# SPC1169 register map
File version: 2022071043481212
CPU: cm4 r1p0, little endian, no MPU, FPU, 4 interrupt priority bits
Registers are 32-bit, read-write, reset 0x0 unless marked. A register's access mark holds for its fields unless they carry their own. Offsets are from the block's base; [hi:lo] are bit positions; {n}, {i} and the like mark numbered series; 'fields as' and 'values as' point back to an identical list.

## SYSTEM
Base 0x40000000
0x00 CID0 ro — Chip ID Register 0
  [31:0] VAL — 32 LSBs of the 64-bit chip ID
0x04 CID1 ro — Chip ID Register 1
  [31:0] VAL — 32 MSBs of the 64-bit chip ID
0x08 UID0 ro — Unique ID Register 0
  [31:0] VAL — 32 LSBs of the 64-bit unique ID
0x0C UID1 ro — Unique ID Register 1
  [31:0] VAL — 32 MSBs of the 64-bit unique ID
0x10 RND0 ro — Random Number Register 0
  [31:0] VAL — 32 LSBs of the 64-bit random number
0x14 RND1 ro — Random Number Register 1
  [31:0] VAL — 32 MSBs of the 64-bit random number
0x18 REV0 ro reset 0x63681010 — Revision Information Register 0
  [31:0] VAL — 32 LSBs of the 64-bit revision number
0x1C REV1 ro reset 0x20200200 — Revision Information Register 1
  [31:0] VAL — 32 MSBs of the 64-bit revision number
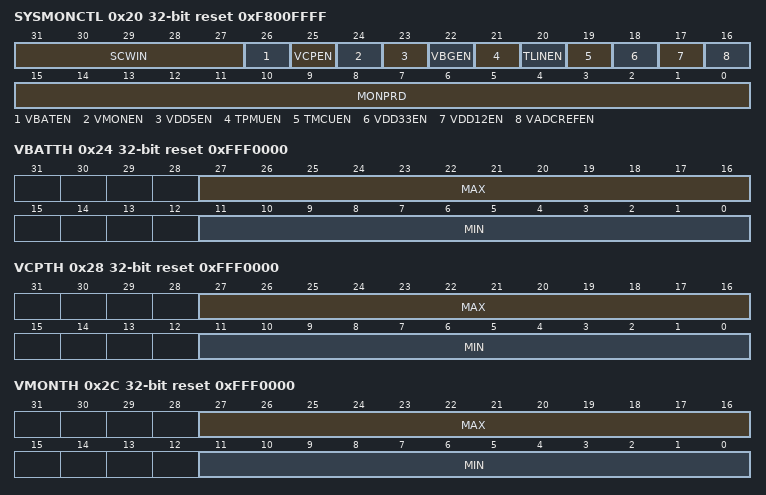
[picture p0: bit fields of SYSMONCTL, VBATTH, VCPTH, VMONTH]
0x20 SYSMONCTL reset 0xF800FFFF — System Monitor Control Register
  [31:27] SCWIN — Both sample and convert time is set to (SCWIN + 1)*4 HCLK cycles
  [26] VBATEN — VBAT monitor enable
    0=DISABLE; 1=ENABLE
  [25] VCPEN — VCP monitor enable
    0=DISABLE; 1=ENABLE
  [24] VMONEN — VMON monitor enable
    0=DISABLE; 1=ENABLE
  [23] VDD5EN — VDD5 monitor enable
    0=DISABLE; 1=ENABLE
  [22] VBGEN — Power bandgap monitor enable
    0=DISABLE; 1=ENABLE
  [21] TPMUEN — Power temperature monitor enable
    0=DISABLE; 1=ENABLE
  [20] TLINEN — LIN PHY temperature monitor enable
    0=DISABLE; 1=ENABLE
  [19] TMCUEN — Controller temperature monitor enable
    0=DISABLE; 1=ENABLE
  [18] VDD33EN — VDD33 monitor enable
    0=DISABLE; 1=ENABLE
  [17] VDD12EN — VDD12 monitor enable
    0=DISABLE; 1=ENABLE
  [16] VADCREFEN — 13-bit ADC reference voltage monitor enable
    0=DISABLE; 1=ENABLE
  [15:0] MONPRD — System monitor interval. i.e. Wait for (MONPRD*8+1) HCLK cycles to measure the next item
0x24 VBATTH reset 0xFFF0000 — VBAT Monitor Threshold Register
  [27:16] MAX — Maximum allowed VBAT monitor code
  [11:0] MIN — Minimum allowed VBAT monitor code
0x28 VCPTH reset 0xFFF0000 — VCP Monitor Threshold Register
  [27:16] MAX — Maximum allowed VCP monitor code
  [11:0] MIN — Minimum allowed VCP monitor code
0x2C VMONTH reset 0xFFF0000 — VMON Monitor Threshold Register
  [27:16] MAX — Maximum allowed VMON monitor code
  [11:0] MIN — Minimum allowed VMON monitor code
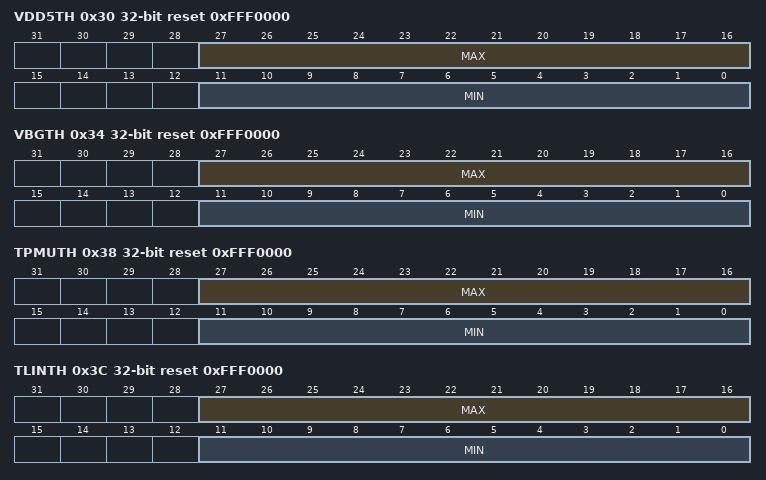
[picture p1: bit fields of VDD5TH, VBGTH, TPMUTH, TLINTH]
0x30 VDD5TH reset 0xFFF0000 — VDD5 Monitor Threshold Register
  [27:16] MAX — Maximum allowed VDD5 monitor code
  [11:0] MIN — Minimum allowed VDD5 monitor code
0x34 VBGTH reset 0xFFF0000 — Power Bandgap Monitor Threshold Register
  [27:16] MAX — Maximum allowed power bandgap monitor code
  [11:0] MIN — Minimum allowed power bandgap monitor code
0x38 TPMUTH reset 0xFFF0000 — Power Module Temperature Monitor Threshold Register
  [27:16] MAX — Maximum allowed power module temperature code
  [11:0] MIN — Minimum allowed power module temperature code
0x3C TLINTH reset 0xFFF0000 — LIN PHY Temperature Monitor Threshold Register
  [27:16] MAX — Maximum allowed LIN PHY temperature code
  [11:0] MIN — Minimum allowed LIN PHY temperature code
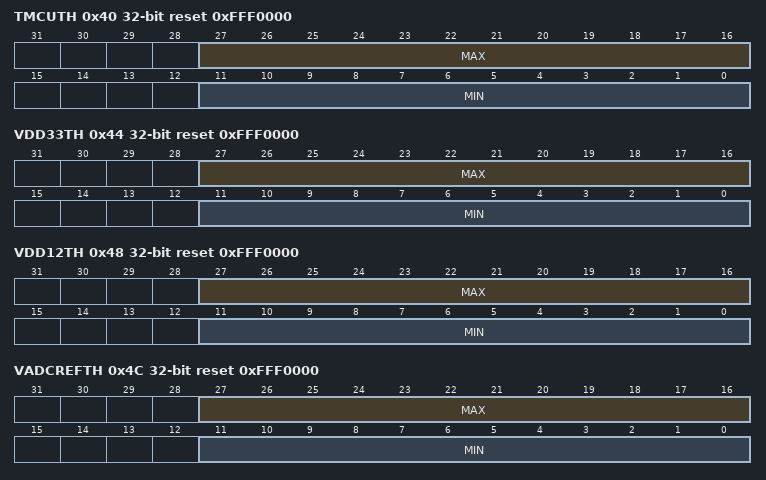
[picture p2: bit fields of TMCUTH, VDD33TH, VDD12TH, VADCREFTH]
0x40 TMCUTH reset 0xFFF0000 — Controller Temperature Monitor Threshold Register
  [27:16] MAX — Maximum allowed controller temperature code
  [11:0] MIN — Minimum allowed controller temperature code
0x44 VDD33TH reset 0xFFF0000 — VDD33 Monitor Threshold Register
  [27:16] MAX — Maximum allowed VDD33 monitor code
  [11:0] MIN — Minimum allowed VDD33 monitor code
0x48 VDD12TH reset 0xFFF0000 — VDD12 Monitor Threshold Register
  [27:16] MAX — Maximum allowed VDD12 monitor code
  [11:0] MIN — Minimum allowed VDD12 monitor code
0x4C VADCREFTH reset 0xFFF0000 — 13-bit ADC Reference Voltage Monitor Threshold Register
  [27:16] MAX — Maximum allowed 13-bit ADC reference monitor code
  [11:0] MIN — Minimum allowed 13-bit ADC reference monitor code
0x50 VBATCODE ro — VBAT Monitor Code Register
  [31:0] CODE — Measured VBAT code
0x54 VCPCODE ro — VCP Monitor Code Register
  [31:0] CODE — Measured VCP code
0x58 VMONCODE ro — VMON Monitor Code Register
  [31:0] CODE — Measured VMON code
0x5C VDD5CODE ro — VDD5 Monitor Code Register
  [31:0] CODE — Measured VDD5 code
0x60 VBGCODE ro — Power Bandgap Monitor Code Register
  [31:0] CODE — Measured power bandgap code
0x64 TPMUCODE ro — Power Module Temperature Monitor Code Register
  [31:0] CODE — Measured power module temperature code
0x68 TLINCODE ro — LIN PHY Temperature Monitor Code Register
  [31:0] CODE — Measured LIN PHY temperature code
0x6C TMCUCODE ro — Controller Temperature Monitor Code Register
  [31:0] CODE — Measured controller temperature code
0x70 VDD33CODE ro — VDD33 Monitor Code Register
  [31:0] CODE — Measured VDD33 code
0x74 VDD12CODE ro — VDD12 Monitor Threshold Register
  [31:0] CODE — Measured VDD12 code
0x78 VADCREFCODE ro — 13-bit ADC Reference Voltage Monitor Code Register
  [31:0] CODE — Measured 13-bit ADC reference code
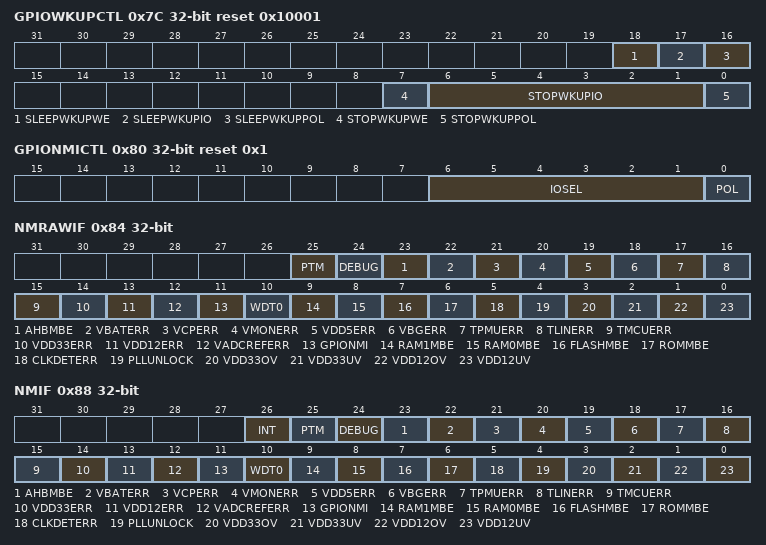
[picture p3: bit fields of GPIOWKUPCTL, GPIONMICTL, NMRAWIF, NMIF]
0x7C GPIOWKUPCTL reset 0x10001 — GPIO Wake-Up Control Register
  [18] SLEEPWKUPWE — GPIO wake up from sleep state write enable. This bit should be write 1 at the same time when write SLEEPWKUPIO and SLEEPWKUPPOL bits
    0=DISABLE; 1=ENABLE
  [17] SLEEPWKUPIO — GPIO number to wake up from sleep state
    0=GPIO28 (Use GPIO28 to wake up the MCU from sleep); 1=GPIO4 (Use GPIO4 to wake up the MCU from sleep)
  [16] SLEEPWKUPPOL — GPIO level to wake up from sleep state
    0=ACTIVE_LOW (Wake up from sleep when low); 1=ACTIVE_HIGH (Wake up from sleep when high)
  [7] STOPWKUPWE — GPIO wake up from stop state write enable. This bit should be write 1 at the same time when write STOPWKUPIO and STOPWKUPPOL bits
    0=DISABLE; 1=ENABLE
  [6:1] STOPWKUPIO — GPIO number to wake up from stop state
  [0] STOPWKUPPOL — GPIO level to wake up from stop state
    0=ACTIVE_LOW (Wake up from stop when low); 1=ACTIVE_HIGH (Wake up from stop when high)
0x80 GPIONMICTL reset 0x1 — GPIO Non-Maskable Interrupt Control Register
  [6:1] IOSEL — GPIO number to trigger the NMI
  [0] POL — GPIO edge to trigger the NMI
    0=FALLING_EDGE; 1=RISING_EDGE
0x84 NMRAWIF ro — Non-Maskable Interrupt Raw Flag Register
  [all] fields
    0=NOT_OCCUR (Event does not occur); 1=OCCUR (Event occurred)
  [25] PTM — Latched production test mode entry flag
  [24] DEBUG — Latched debug mode entry flag
  [23] AHBMBE — Latched AHB address or data ECC multi-bit error flag
  [22] VBATERR — Latched VBAT monitor error flag
  [21] VCPERR — Latched VCP monitor error flag
  [20] VMONERR — Latched VMON monitor error flag
  [19] VDD5ERR — Latched VDD5 monitor error flag
  [18] VBGERR — Latched power bandgap monitor error flag
  [17] TPMUERR — Latched power module temperature monitor error flag
  [16] TLINERR — Latched LIN PHY temperature monitor error flag
  [15] TMCUERR — Latched controller temperature monitor error flag
  [14] VDD33ERR — Latched VDD33 monitor error flag
  [13] VDD12ERR — Latched VDD12 monitor error flag
  [12] VADCREFERR — Latched 13-bit ADC reference monitor error flag
  [11] GPIONMI — Latched GPIO non-maskable interrupt event flag
  [10] WDT0 — Latched WDT0 timeout flag
  [9] RAM1MBE — Latched RAM1 ECC multi-bit error flag
  [8] RAM0MBE — Latched RAM0 ECC multi-bit error flag
  [7] FLASHMBE — Latched FLASH ECC multi-bit error flag
  [6] ROMMBE — Latched ROM ECC multi-bit error flag
  [5] CLKDETERR — Latched CLKDET error event flag. It means CLKDETCNT is out of the range defined by CLKDETCTH
  [4] PLLUNLOCK — Latched PLL unlock event flag. Detailed reason can be referred to CLKSTS[PLLFAST] and CLKSTS[PLLSLOW]
  [3] VDD33OV — Latched VDD33 over-voltage event flag
  [2] VDD33UV — Latched VDD33 under-voltage event flag
  [1] VDD12OV — Latched VDD12 over-volage event flag
  [0] VDD12UV — Latched VDD12 under-volage event flag
0x88 NMIF ro — Non-Maskable Interrupt Flag Register
  [26] INT — Global non-maskable interrupt flag
    0=NOT_OCCUR (Non-maskable interrupt does not occur); 1=OCCUR (Non-maskable interrupt occurred and issued to the CPU. Further interrupt will not be generated until this bit is cleared.)
  [25] PTM — Latched production test mode entry interrupt flag
    0=NOT_OCCUR (Interrupt does not occur); 1=OCCUR (Interrupt occurred. Futher event will not trigger interrupt until this bit is cleared)
  [24] DEBUG — Latched debug mode entry interrupt flag
    values as PTM
  [23] AHBMBE — Latched AHB address or data ECC multi-bit error interrupt flag
    values as PTM
  [22] VBATERR — Latched VBAT monitor error interrupt flag
    values as PTM
  [21] VCPERR — Latched VCP monitor error interrupt flag
    values as PTM
  [20] VMONERR — Latched VMON monitor error interrupt flag
    values as PTM
  [19] VDD5ERR — Latched VDD5 monitor error interrupt flag
    values as PTM
  [18] VBGERR — Latched power bandgap monitor error interrupt flag
    values as PTM
  [17] TPMUERR — Latched power module temperature monitor error interrupt flag
    values as PTM
  [16] TLINERR — Latched LIN PHY temperature monitor error interrupt flag
    values as PTM
  [15] TMCUERR — Latched controller temperature monitor error interrupt flag
    values as PTM
  [14] VDD33ERR — Latched VDD33 monitor error interrupt flag
    values as PTM
  [13] VDD12ERR — Latched VDD12 monitor error interrupt flag
    values as PTM
  [12] VADCREFERR — Latched 13-bit ADC reference monitor error interrupt flag
    values as PTM
  [11] GPIONMI — Latched GPIO non-maskable interrupt flag
    values as PTM
  [10] WDT0 — Latched WDT0 interrupt flag
    values as PTM
  [9] RAM1MBE — Latched RAM1 ECC multi-bit error interrupt flag
    values as PTM
  [8] RAM0MBE — Latched RAM0 ECC multi-bit error interrupt flag
    values as PTM
  [7] FLASHMBE — Latched FLASH ECC multi-bit error interrupt flag
    values as PTM
  [6] ROMMBE — Latched ROM ECC multi-bit error interrupt flag
    values as PTM
  [5] CLKDETERR — Latched CLKDET error interrupt flag
    values as PTM
  [4] PLLUNLOCK — Latched PLL unlock interrupt flag
    values as PTM
  [3] VDD33OV — Latched VDD33 over-voltage interrupt flag
    values as PTM
  [2] VDD33UV — Latched VDD33 under-voltage interrupt flag
    values as PTM
  [1] VDD12OV — Latched VDD12 over-volage interrupt flag
    values as PTM
  [0] VDD12UV — Latched VDD12 under-volage interrupt flag
    values as PTM
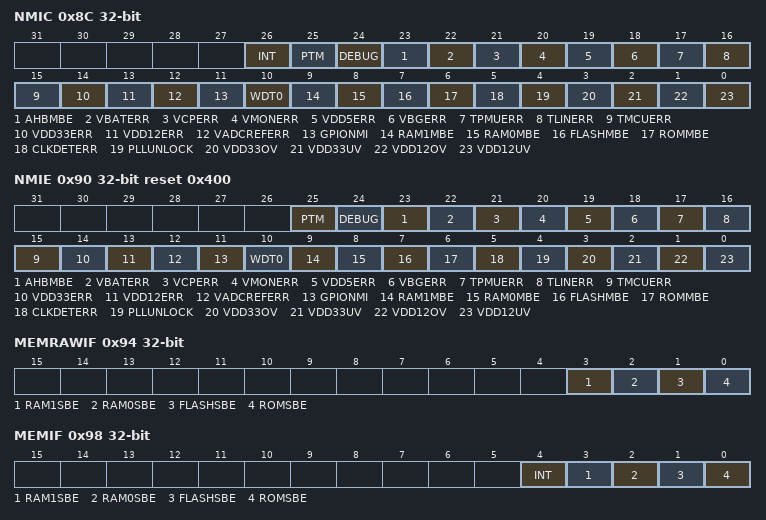
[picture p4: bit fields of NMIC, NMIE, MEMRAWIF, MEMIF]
0x8C NMIC — Non-Maskable Interrupt Clear Register
  [all] fields
    0=NO_EFFECT (Write 0 has no effect and always reads back 0); 1=CLEAR (Write 1 clears the flag. This bit is self-cleared.)
  [26] INT — Global non-maskable interrupt clear
  [25] PTM — Latched production test mode entry interrupt clear
  [24] DEBUG — Latched debug mode entry interrupt clear
  [23] AHBMBE — AHB address or data ECC multi-bit error interrupt clear
  [22] VBATERR — VBAT monitor error interrupt clear
  [21] VCPERR — VCP monitor error interrupt clear
  [20] VMONERR — VMON monitor error interrupt clear
  [19] VDD5ERR — VDD5 monitor error interrupt clear
  [18] VBGERR — Power bandgap monitor error interrupt clear
  [17] TPMUERR — Power module temperature monitor error interrupt clear
  [16] TLINERR — LIN PHY temperature monitor error interrupt clear
  [15] TMCUERR — Controller temperature monitor error interrupt clear
  [14] VDD33ERR — VDD33 monitor error interrupt clear
  [13] VDD12ERR — VDD12 monitor error interrupt clear
  [12] VADCREFERR — 13-bit ADC reference monitor error interrupt clear
  [11] GPIONMI — GPIO non-maskable interrupt clear
  [10] WDT0 — WDT0 interrupt clear. This bit is equivalent to WDTIC register bit of WDT0
  [9] RAM1MBE — RAM1 ECC multi-bit error interrupt clear
  [8] RAM0MBE — RAM0 ECC multi-bit error interrupt clear
  [7] FLASHMBE — FLASH ECC multi-bit error interrupt clear
  [6] ROMMBE — ROM ECC multi-bit error interrupt clear
  [5] CLKDETERR — CLKDET error interrupt clear
  [4] PLLUNLOCK — PLL unlock interrupt clear
  [3] VDD33OV — VDD33 over-voltage interrupt clear
  [2] VDD33UV — VDD33 under-voltage interrupt clear
  [1] VDD12OV — VDD12 over-volage interrupt clear
  [0] VDD12UV — VDD12 under-volage interrupt clear
0x90 NMIE reset 0x400 — Non-Maskable Interrupt Enable Register
  [all] fields
    0=DISABLE; 1=ENABLE
  [25] PTM — Production test mode entry interrupt enable
  [24] DEBUG — Debug mode entry interrupt enable
  [23] AHBMBE — AHB address or data ECC multi-bit error interrupt enable
  [22] VBATERR — VBAT monitor error interrupt enable
  [21] VCPERR — VCP monitor error interrupt enable
  [20] VMONERR — VMON monitor error interrupt enable
  [19] VDD5ERR — VDD5 monitor error interrupt enable
  [18] VBGERR — Power bandgap monitor error interrupt enable
  [17] TPMUERR — Power module temperature monitor error interrupt enable
  [16] TLINERR — LIN PHY temperature monitor error interrupt enable
  [15] TMCUERR — Controller temperature monitor error interrupt enable
  [14] VDD33ERR — VDD33 monitor error interrupt enable
  [13] VDD12ERR — VDD12 monitor error interrupt enable
  [12] VADCREFERR — 13-bit ADC reference monitor error interrupt enable
  [11] GPIONMI — GPIO non-maskable interrupt enable
  [10] WDT0 — WDT0 interrupt enable. This bit is equivalent to WDTIE register bit of WDT0
  [9] RAM1MBE — RAM1 ECC multi-bit error interrupt enable
  [8] RAM0MBE — RAM0 ECC multi-bit error interrupt enable
  [7] FLASHMBE — FLASH ECC multi-bit error interrupt enable
  [6] ROMMBE — ROM ECC multi-bit error interrupt enable
  [5] CLKDETERR — CLKDET error interrupt enable
  [4] PLLUNLOCK — PLL unlock interrupt enable
  [3] VDD33OV — VDD33 over-voltage interrupt enable
  [2] VDD33UV — VDD33 under-voltage interrupt enable
  [1] VDD12OV — VDD12 over-volage interrupt enable
  [0] VDD12UV — VDD12 under-volage interrupt enable
0x94 MEMRAWIF ro — Memory Interrupt Raw Flag Register
  [all] fields
    0=NOT_OCCUR (Event does not occur); 1=OCCUR (Event occurred)
  [3] RAM1SBE — Latched RAM1 single-bit error event flag
  [2] RAM0SBE — Latched RAM0 single-bit error event flag
  [1] FLASHSBE — Latched FLASH single-bit error event flag
  [0] ROMSBE — Latched ROM single-bit error event flag
0x98 MEMIF ro — Non-Maskable Interrupt Flag Register
  [4] INT — Global memory error interrupt flag
    0=NOT_OCCUR (Interrupt does not occur); 1=OCCUR (Interrupt occurred. Futher interrupt will not be generated until this bit is cleared)
  [3] RAM1SBE — Latched ECC RAM1 single-bit error interrupt flag
    values as NMIF.PTM
  [2] RAM0SBE — Latched ECC RAM0 single-bit error interrupt flag
    values as NMIF.PTM
  [1] FLASHSBE — Latched ECC FLASH single-bit error interrupt flag
    values as NMIF.PTM
  [0] ROMSBE — Latched ECC ROM single-bit error interrupt flag
    values as NMIF.PTM
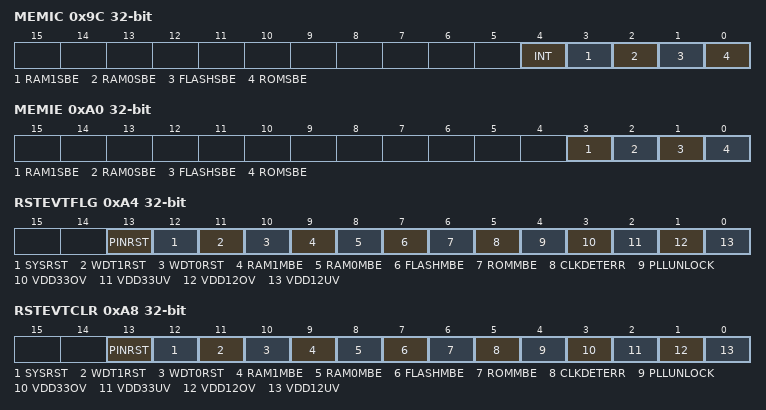
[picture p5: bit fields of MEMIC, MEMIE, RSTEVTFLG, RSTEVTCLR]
0x9C MEMIC — Memory Interrupt Clear Register
  [all] fields
    values as the fields of NMIC
  [4] INT — Global memory error interrupt clear
  [3] RAM1SBE — RAM1 ECC single-bit error interrupt clear
  [2] RAM0SBE — RAM0 ECC single-bit error interrupt clear
  [1] FLASHSBE — FLASH ECC single-bit error interrupt clear
  [0] ROMSBE — ROM ECC single-bit error interrupt clear
0xA0 MEMIE — Memory Interrupt Enable Register
  [all] fields
    0=DISABLE; 1=ENABLE
  [3] RAM1SBE — RAM1 ECC single-bit error interrupt enable
  [2] RAM0SBE — RAM0 ECC single-bit error interrupt enable
  [1] FLASHSBE — FLASH ECC single-bit error interrupt enable
  [0] ROMSBE — ROM ECC single-bit error interrupt enable
0xA4 RSTEVTFLG ro — Reset Event Flag Register
  [13] PINRST — Latched reset flag upon XRSTn pin reset event
    0=NOT_OCCUR (Specified reset not happen); 1=OCCUR (Specified reset happened)
  [12] SYSRST — Latched reset flag upon system reset event
    values as PINRST
  [11] WDT1RST — Latched reset flag upon WDT1 reset event
    values as PINRST
  [10] WDT0RST — Latched reset flag upon WDT0 reset event
    values as PINRST
  [9] RAM1MBE — Latched reset flag upon RAM1 multi-bit error event
    0=NOT_OCCUR (Specified reset does not happen); 1=OCCUR (Specified reset happened)
  [8] RAM0MBE — Latched reset flag upon RAM0 multi-bit error event
    values as RAM1MBE
  [7] FLASHMBE — Latched reset flag upon FLASH multi-bit error event
    values as RAM1MBE
  [6] ROMMBE — Latched reset flag upon ROM multi-bit error event
    values as RAM1MBE
  [5] CLKDETERR — Latched reset flag upon CLKDETERR event
    values as PINRST
  [4] PLLUNLOCK — Latched reset flag upon PLL unlock event
    values as PINRST
  [3] VDD33OV — Latched reset flag upon VDD33OV event
    values as RAM1MBE
  [2] VDD33UV — Latched reset flag upon VDD33UV event
    values as RAM1MBE
  [1] VDD12OV — Latched reset flag upon VDD12OV event
    values as RAM1MBE
  [0] VDD12UV — Latched reset flag upon VDD12UV event
    values as RAM1MBE
0xA8 RSTEVTCLR — Reset Event Flag Clear Register
  [all] fields
    values as the fields of NMIC
  [13] PINRST — Clear reset flag upon XRSTn pin reset event
  [12] SYSRST — Clear reset flag upon system reset event
  [11] WDT1RST — Clear reset flag upon WDT1 reset event
  [10] WDT0RST — Clear reset flag upon WDT0 reset event
  [9] RAM1MBE — Clear reset flag upon RAM1 multi-bit error event
  [8] RAM0MBE — Clear reset flag upon RAM0 multi-bit error event
  [7] FLASHMBE — Clear reset flag upon FLASH multi-bit error event
  [6] ROMMBE — Clear reset flag upon ROM multi-bit error event
  [5] CLKDETERR — Clear reset flag upon CLKDETERR event
  [4] PLLUNLOCK — Clear reset flag upon PLL unlock event
  [3] VDD33OV — Clear reset flag upon VDD33OV event
  [2] VDD33UV — Clear reset flag upon VDD33UV event
  [1] VDD12OV — Clear reset flag upon VDD12OV event
  [0] VDD12UV — Clear reset flag upon VDD12UV event
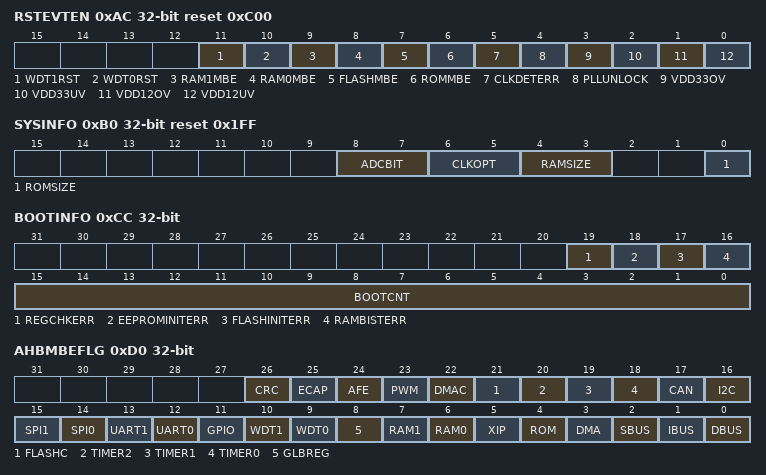
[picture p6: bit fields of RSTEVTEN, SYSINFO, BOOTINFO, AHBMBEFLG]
0xAC RSTEVTEN reset 0xC00 — Reset Event Enable Register
  [all] fields
    0=DISABLE; 1=ENABLE
  [11] WDT1RST — Enable reset upon WDT1 reset request
  [10] WDT0RST — Enable reset upon WDT0 reset request
  [9] RAM1MBE — Enable reset upon RAM1 multi-bit error event
  [8] RAM0MBE — Enable reset upon RAM0 multi-bit error event
  [7] FLASHMBE — Enable reset upon FLASH multi-bit error event
  [6] ROMMBE — Enable reset upon ROM multi-bit error event
  [5] CLKDETERR — Enable reset upon CLKDETERR event
  [4] PLLUNLOCK — Enable reset upon PLL unlock event
  [3] VDD33OV — Enable reset upon VDD33OV event
  [2] VDD33UV — Enable reset upon VDD33UV event
  [1] VDD12OV — Enable reset upon VDD12OV event
  [0] VDD12UV — Enable reset upon VDD12UV event
0xB0 SYSINFO ro reset 0x1FF — System Information Register
  [8:7] ADCBIT — ADC bit resolution
    {v}={v+10}_BIT (v=0..3)
  [6:5] CLKOPT — Clock option
    0=50_MHz_NO_XO (Minimum PLL output dividng ratio is 12 and no XO); 1=100_MHz_NO_XO (Minimum PLL output dividing ratio is 6 and no XO); 2=50_MHZ (Minimum PLL output dividng ratio is 12); 3=100_MHZ (Minimum PLL output dividing ratio is 6)
  [4:3] RAMSIZE
    0=8_KB (8KB from 0x20000000 to 0x20001FFF); 1=10_KB (10KB from 0x1FFFF800 to 0x20001FFF); 2=12_KB (12KB from 0x1FFFF000 to 0x20001FFF); 3=16_KB (16KB from 0x1FFFE000 to 0x20001FFF)
  [0] ROMSIZE
    0=BASIC (Basic support); 1=FULL (Full support with motor hardware libraries)
0xB4 ROMERRADDR ro reset 0xFFFFFFFF — ROM ECC Error Address
  [31:0] VAL — Address where ECC error happened for ROM access
0xB8 FLASHERRADDR ro reset 0xFFFFFFFF — FLASH ECC Error Address
  [31:0] VAL — Address where ECC error happened for FLASH access
0xBC RAM0ERRADDR ro reset 0xFFFFFFFF — RAM0 ECC Error Address
  [31:0] VAL — Address where ECC error happened for RAM0 access
0xC0 RAM1ERRADDR ro reset 0xFFFFFFFF — RAM1 ECC Error Address
  [31:0] VAL — Address where ECC error happened for RAM1 access
0xC8 DBGIFCTL — Debug Interface Control Register
  [0] JTAGMODE — JTAG or SWD debug interface select
    0=SWD_MODE; 1=JTAG_MODE
0xCC BOOTINFO — Boot Information Register
  [19] REGCHKERR — Critical register reset default value error
    0=PASS (Register default value is correct); 1=FAIL (Register default value is not correct)
  [18] EEPROMINITERR — EEPROM initialization error
    0=PASS (EEPROM initialization passed); 1=FAIL (EEPROM initialization failed)
  [17] FLASHINITERR — FLASH initialization error
    0=PASS (FLASH initialization passed); 1=FAIL (FALSH initialization failed)
  [16] RAMBISTERR — RAM built-in self test error
    0=PASS (RAM test passed); 1=FAIL (RAM test failed)
  [15:0] BOOTCNT — Boot counter, increaed by 1 when each time boot code is executed
0xD0 AHBMBEFLG ro — AHB Multi-Bit ECC Error Event Flag Register
  [all] fields
    0=NOT_OCCUR (Event does not occur); 1=OCCUR (Event occurred)
  [26] CRC — CRC AHB port multi-bit ECC error event flag
  [25] ECAP — ECAP AHB port multi-bit ECC error event flag
  [24] AFE — AFE AHB port multi-bit ECC error event flag
  [23] PWM — PWM AHB port multi-bit ECC error event flag
  [22] DMAC — DMAC AHB port multi-bit ECC error event flag
  [21] FLASHC — FLASHC AHB port multi-bit ECC error event flag
  [20] TIMER2 — TIMER2 AHB port multi-bit ECC error event flag
  [19] TIMER1 — TIMER1 AHB port multi-bit ECC error event flag
  [18] TIMER0 — TIMER0 AHB port multi-bit ECC error event flag
  [17] CAN — CAN AHB port multi-bit ECC error event flag
  [16] I2C — I2C AHB port multi-bit ECC error event flag
  [15] SPI1 — SPI1 AHB port multi-bit ECC error event flag
  [14] SPI0 — SPI0 AHB port multi-bit ECC error event flag
  [13] UART1 — UART1 AHB port multi-bit ECC error event flag
  [12] UART0 — UART0 AHB port multi-bit ECC error event flag
  [11] GPIO — GPIO AHB port multi-bit ECC error event flag
  [10] WDT1 — WDT1 AHB port multi-bit ECC error event flag
  [9] WDT0 — WDT0 AHB port multi-bit ECC error event flag
  [8] GLBREG — Global control AHB port multi-bit ECC error event flag
  [7] RAM1 — RAM1 AHB port multi-bit ECC error event flag
  [6] RAM0 — RAM0 AHB port multi-bit ECC error event flag
  [5] XIP — XIP AHB port multi-bit ECC error event flag
  [4] ROM — ROM AHB port multi-bit ECC error event flag
  [3] DMA — DMA AHB port multi-bit ECC error event flag
  [2] SBUS — S-bus multi-bit ECC error event flag
  [1] IBUS — I-bus multi-bit ECC error event flag
  [0] DBUS — D-bus multi-bit ECC error event flag
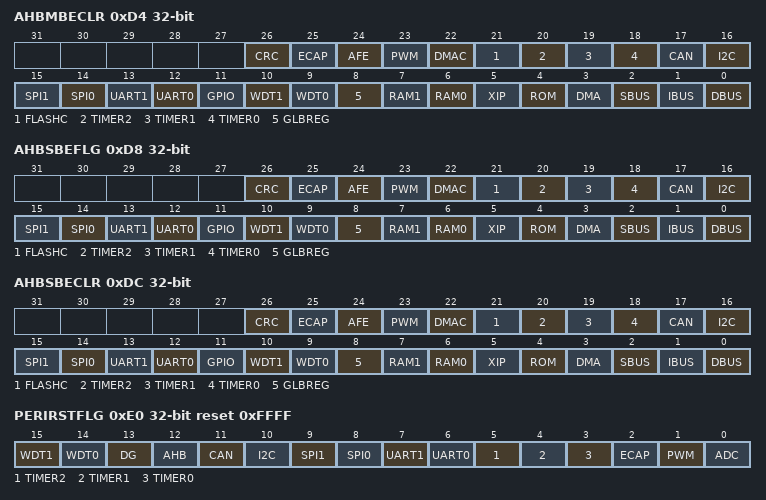
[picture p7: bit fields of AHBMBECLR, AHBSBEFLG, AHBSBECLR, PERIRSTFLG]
0xD4 AHBMBECLR — AHB Multi-bit ECC Error Event Flag Register
  [all] fields
    values as the fields of NMIC
  [26] CRC — CRC AHB port uncorrectable ECC error event flag clear
  [25] ECAP — ECAP AHB port uncorrectable ECC error event flag clear
  [24] AFE — AFE AHB port uncorrectable ECC error event flag clear
  [23] PWM — PWM AHB port uncorrectable ECC error event flag clear
  [22] DMAC — DMAC AHB port uncorrectable ECC error event flag clear
  [21] FLASHC — FLASHC AHB port uncorrectable ECC error event flag clear
  [20] TIMER2 — TIMER2 AHB port uncorrectable ECC error event flag clear
  [19] TIMER1 — TIMER1 AHB port uncorrectable ECC error event flag clear
  [18] TIMER0 — TIMER0 AHB port uncorrectable ECC error event flag clear
  [17] CAN — CAN AHB port uncorrectable ECC error event flag clear
  [16] I2C — I2C AHB port uncorrectable ECC error event flag clear
  [15] SPI1 — SPI1 AHB port uncorrectable ECC error event flag clear
  [14] SPI0 — SPI0 AHB port uncorrectable ECC error event flag clear
  [13] UART1 — UART1 AHB port uncorrectable ECC error event flag clear
  [12] UART0 — UART0 AHB port uncorrectable ECC error event flag clear
  [11] GPIO — GPIO AHB port uncorrectable ECC error event flag clear
  [10] WDT1 — WDT1 AHB port uncorrectable ECC error event flag clear
  [9] WDT0 — WDT0 AHB port uncorrectable ECC error event flag clear
  [8] GLBREG — Global control AHB port uncorrectable ECC error event flag clear
  [7] RAM1 — RAM1 AHB port uncorrectable ECC error event flag clear
  [6] RAM0 — RAM0 AHB port uncorrectable ECC error event flag clear
  [5] XIP — XIP AHB port uncorrectable ECC error event flag clear
  [4] ROM — ROM AHB port uncorrectable ECC error event flag clear
  [3] DMA — DMA AHB port uncorrectable ECC error event flag clear
  [2] SBUS — S-bus uncorrectable ECC error event flag clear
  [1] IBUS — I-bus uncorrectable ECC error event flag clear
  [0] DBUS — D-bus uncorrectable ECC error event flag clear
0xD8 AHBSBEFLG ro — AHB Single-Bit ECC Error Event Flag Register
  [all] fields
    0=NOT_OCCUR (Event does not occur); 1=OCCUR (Event occurred)
  [26] CRC — CRC AHB port Single-bit ECC error event flag
  [25] ECAP — ECAP AHB port Single-bit ECC error event flag
  [24] AFE — AFE AHB port Single-bit ECC error event flag
  [23] PWM — PWM AHB port Single-bit ECC error event flag
  [22] DMAC — DMAC AHB port Single-bit ECC error event flag
  [21] FLASHC — FLASHC AHB port Single-bit ECC error event flag
  [20] TIMER2 — TIMER2 AHB port Single-bit ECC error event flag
  [19] TIMER1 — TIMER1 AHB port Single-bit ECC error event flag
  [18] TIMER0 — TIMER0 AHB port Single-bit ECC error event flag
  [17] CAN — CAN AHB port Single-bit ECC error event flag
  [16] I2C — I2C AHB port Single-bit ECC error event flag
  [15] SPI1 — SPI1 AHB port Single-bit ECC error event flag
  [14] SPI0 — SPI0 AHB port Single-bit ECC error event flag
  [13] UART1 — UART1 AHB port Single-bit ECC error event flag
  [12] UART0 — UART0 AHB port Single-bit ECC error event flag
  [11] GPIO — GPIO AHB port Single-bit ECC error event flag
  [10] WDT1 — WDT1 AHB port Single-bit ECC error event flag
  [9] WDT0 — WDT0 AHB port Single-bit ECC error event flag
  [8] GLBREG — Global control AHB port Single-bit ECC error event flag
  [7] RAM1 — RAM1 AHB port Single-bit ECC error event flag
  [6] RAM0 — RAM0 AHB port Single-bit ECC error event flag
  [5] XIP — XIP AHB port Single-bit ECC error event flag
  [4] ROM — ROM AHB port Single-bit ECC error event flag
  [3] DMA — DMA AHB port Single-bit ECC error event flag
  [2] SBUS — S-bus Single-bit ECC error event flag
  [1] IBUS — I-bus Single-bit ECC error event flag
  [0] DBUS — D-bus Single-bit ECC error event flag
0xDC AHBSBECLR — AHB Single-bit ECC Error Event Flag Register
  fields as AHBMBECLR
0xE0 PERIRSTFLG ro reset 0xFFFF — Peripheral Reset Event Flag Register
  [all] fields
    0=OCCUR; 1=NOT_OCCUR
  [15] WDT1 — Watchdog 1 latched reset event flag
  [14] WDT0 — Watchdog 0 latched reset event flag
  [13] DG — Deglitch module latched reset event flag
  [12] AHB — Bus and CPU latched reset event flag
  [11] CAN — CAN module latched reset event flag
  [10] I2C — I2C module latched reset event flag
  [9] SPI1 — SPI1 module latched reset event flag
  [8] SPI0 — SPI0 module latched reset event flag
  [7] UART1 — UART1 module latched reset event flag
  [6] UART0 — UART0 module latched reset event flag
  [5] TIMER2 — TIMER2 module latched reset event flag
  [4] TIMER1 — TIMER1 module latched reset event flag
  [3] TIMER0 — TIMER0 module latched reset event flag
  [2] ECAP — ECAP module latched reset event flag
  [1] PWM — PWM module latched reset event flag
  [0] ADC — ADC module latched reset event flag
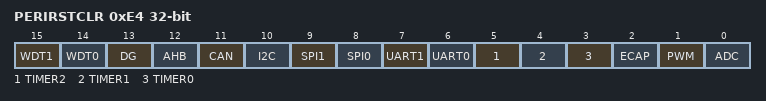
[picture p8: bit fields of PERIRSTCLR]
0xE4 PERIRSTCLR — Peripheral Reset Event Clear Register
  [all] fields
    0=NO_EFFECT; 1=CLEAR
  [15] WDT1 — Watchdog 1 reset event clear
  [14] WDT0 — Watchdog 0 reset event clear
  [13] DG — Deglitch module reset event clear
  [12] AHB — Bus and CPU reset event clear
  [11] CAN — CAN module reset event clear
  [10] I2C — I2C module reset event clear
  [9] SPI1 — SPI1 module reset event clear
  [8] SPI0 — SPI0 module reset event clear
  [7] UART1 — UART1 module reset event clear
  [6] UART0 — UART0 module reset event clear
  [5] TIMER2 — TIMER2 module reset event clear
  [4] TIMER1 — TIMER1 module reset event clear
  [3] TIMER0 — TIMER0 module reset event clear
  [2] ECAP — ECAP module reset event clear
  [1] PWM — PWM module reset event clear
  [0] ADC — ADC module reset event clear
{0xF0+4i} NVREG{i} (i=0..2) — Non-Volatile Register {i}
  [31:0] VAL — Value in this register can only be reset via power-cycling
0xFC SYSREGKEY reset 0x1ACCE551 — System Register Write-Allow Key Register
  [31:0] KEY — Write 0x1ACCE551 to unlock protected system registers
